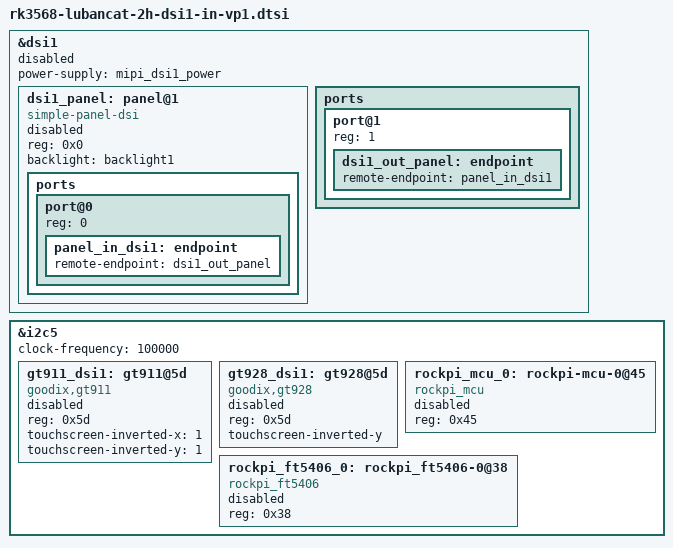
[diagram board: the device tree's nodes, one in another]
// SPDX-License-Identifier: (GPL-2.0+ OR MIT)
&dsi1 {
	status = "disabled";
	power-supply = <&mipi_dsi1_power>;
	#address-cells = <1>;
	#size-cells = <0>;

	dsi1_panel: panel@1 {
		status = "disabled";
		compatible = "simple-panel-dsi";
		reg = <0x0>;
		backlight = <&backlight1>;

		ports {
			#address-cells = <1>;
			#size-cells = <0>;
			port@0 {
				reg = <0>;
				panel_in_dsi1: endpoint {
					remote-endpoint = <&dsi1_out_panel>;
				};
			};
		};
	};

	ports {
		#address-cells = <1>;
		#size-cells = <0>;
		port@1 {
			reg = <1>;
			dsi1_out_panel: endpoint {
				remote-endpoint = <&panel_in_dsi1>;
			};
		};
	};
};

&i2c5 {
	status = "okay";
	clock-frequency = <100000>;
	#address-cells = <1>;
	#size-cells = <0>;

	gt911_dsi1: gt911@5d {
		status = "disabled";
		compatible = "goodix,gt911";
		reg = <0x5d>;
		touchscreen-inverted-x = <1>;
		touchscreen-inverted-y = <1>;
	};

	gt928_dsi1: gt928@5d {
		status = "disabled";
		compatible = "goodix,gt928";
		reg = <0x5d>;
		touchscreen-inverted-y;
	};

	rockpi_mcu_0: rockpi-mcu-0@45 {
		compatible = "rockpi_mcu";
		reg = <0x45>;
		status = "disabled";
	};

	rockpi_ft5406_0: rockpi_ft5406-0@38 {
		compatible = "rockpi_ft5406";
		reg = <0x38>;
		status = "disabled";
	};

};

